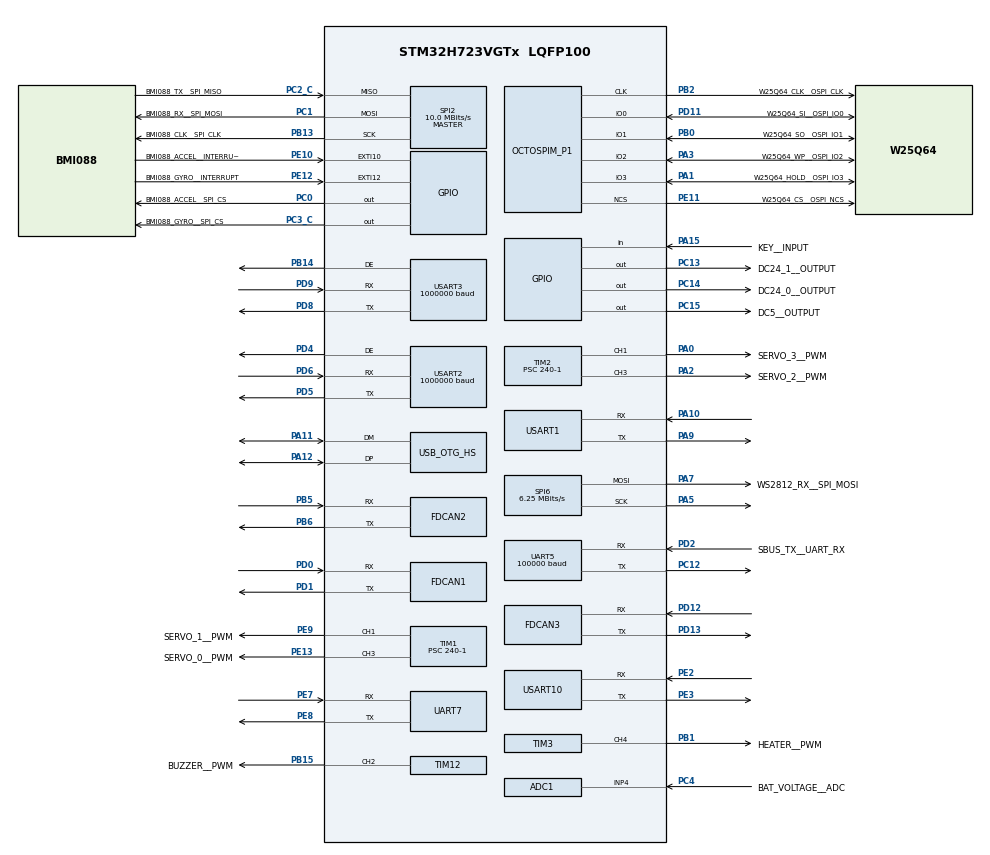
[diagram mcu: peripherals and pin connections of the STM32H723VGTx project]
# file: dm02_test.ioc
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ADC1.Channel-0\#ChannelRegularConversion=ADC_CHANNEL_4
ADC1.ClockPrescaler=ADC_CLOCK_ASYNC_DIV128
ADC1.ContinuousConvMode=ENABLE
ADC1.ConversionDataManagement=ADC_CONVERSIONDATA_DMA_CIRCULAR
ADC1.NbrOfConversion=1
ADC1.NbrOfConversionFlag=1
ADC1.OffsetNumber-0\#ChannelRegularConversion=ADC_OFFSET_NONE
ADC1.OffsetSignedSaturation-0\#ChannelRegularConversion=DISABLE
ADC1.Rank-0\#ChannelRegularConversion=1
ADC1.SamplingTime-0\#ChannelRegularConversion=ADC_SAMPLETIME_32CYCLES_5
ADC1.master=1
CORTEX_M7.BaseAddress_Spec=0x24000000
CORTEX_M7.CPU_DCache=Disabled
CORTEX_M7.CPU_ICache=Enabled
CORTEX_M7.DisableExec_Spec=MPU_INSTRUCTION_ACCESS_ENABLE
CORTEX_M7.IsBufferable_Spec=MPU_ACCESS_BUFFERABLE
CORTEX_M7.IsCacheable_Spec=MPU_ACCESS_CACHEABLE
CORTEX_M7.IsShareable_Spec=MPU_ACCESS_NOT_SHAREABLE
CORTEX_M7.MPU_Control=__NULL
CORTEX_M7.Size_Spec=MPU_REGION_SIZE_512KB
CORTEX_M7.SubRegionDisable_Spec=0x0
CORTEX_M7.TypeExtField_Spec=MPU_TEX_LEVEL1
CORTEX_M7.default_mode_Activation=1
Dma.ADC1.13.Direction=DMA_PERIPH_TO_MEMORY
Dma.ADC1.13.EventEnable=DISABLE
Dma.ADC1.13.FIFOMode=DMA_FIFOMODE_DISABLE
Dma.ADC1.13.Instance=DMA2_Stream5
Dma.ADC1.13.MemDataAlignment=DMA_MDATAALIGN_HALFWORD
Dma.ADC1.13.MemInc=DMA_MINC_ENABLE
Dma.ADC1.13.Mode=DMA_CIRCULAR
Dma.ADC1.13.PeriphDataAlignment=DMA_PDATAALIGN_HALFWORD
Dma.ADC1.13.PeriphInc=DMA_PINC_DISABLE
Dma.ADC1.13.Polarity=HAL_DMAMUX_REQ_GEN_RISING
Dma.ADC1.13.Priority=DMA_PRIORITY_LOW
Dma.ADC1.13.RequestNumber=1
Dma.ADC1.13.SignalID=NONE
Dma.ADC1.13.SyncEnable=DISABLE
Dma.ADC1.13.SyncPolarity=HAL_DMAMUX_SYNC_NO_EVENT
Dma.ADC1.13.SyncRequestNumber=1
Dma.ADC1.13.SyncSignalID=NONE
Dma.Request0=USART2_RX
Dma.Request1=USART2_TX
Dma.Request10=USART10_TX
Dma.Request11=SPI2_RX
Dma.Request12=SPI2_TX
Dma.Request13=ADC1
Dma.Request2=USART3_RX
Dma.Request3=USART3_TX
Dma.Request4=UART5_RX
Dma.Request5=USART1_RX
Dma.Request6=USART1_TX
Dma.Request7=UART7_RX
Dma.Request8=UART7_TX
Dma.Request9=USART10_RX
Dma.SPI2_RX.11.Direction=DMA_PERIPH_TO_MEMORY
Dma.SPI2_RX.11.EventEnable=DISABLE
Dma.SPI2_RX.11.FIFOMode=DMA_FIFOMODE_ENABLE
Dma.SPI2_RX.11.FIFOThreshold=DMA_FIFO_THRESHOLD_FULL
Dma.SPI2_RX.11.Instance=DMA2_Stream3
Dma.SPI2_RX.11.MemBurst=DMA_MBURST_SINGLE
Dma.SPI2_RX.11.MemDataAlignment=DMA_MDATAALIGN_BYTE
Dma.SPI2_RX.11.MemInc=DMA_MINC_ENABLE
Dma.SPI2_RX.11.Mode=DMA_NORMAL
Dma.SPI2_RX.11.PeriphBurst=DMA_PBURST_SINGLE
Dma.SPI2_RX.11.PeriphDataAlignment=DMA_PDATAALIGN_BYTE
Dma.SPI2_RX.11.PeriphInc=DMA_PINC_DISABLE
Dma.SPI2_RX.11.Polarity=HAL_DMAMUX_REQ_GEN_RISING
Dma.SPI2_RX.11.Priority=DMA_PRIORITY_LOW
Dma.SPI2_RX.11.RequestNumber=1
Dma.SPI2_RX.11.SignalID=NONE
Dma.SPI2_RX.11.SyncEnable=DISABLE
Dma.SPI2_RX.11.SyncPolarity=HAL_DMAMUX_SYNC_NO_EVENT
Dma.SPI2_RX.11.SyncRequestNumber=1
Dma.SPI2_RX.11.SyncSignalID=NONE
Dma.SPI2_TX.12.Direction=DMA_MEMORY_TO_PERIPH
Dma.SPI2_TX.12.EventEnable=DISABLE
Dma.SPI2_TX.12.FIFOMode=DMA_FIFOMODE_DISABLE
Dma.SPI2_TX.12.Instance=DMA2_Stream4
Dma.SPI2_TX.12.MemDataAlignment=DMA_MDATAALIGN_BYTE
Dma.SPI2_TX.12.MemInc=DMA_MINC_ENABLE
Dma.SPI2_TX.12.Mode=DMA_NORMAL
Dma.SPI2_TX.12.PeriphDataAlignment=DMA_PDATAALIGN_BYTE
Dma.SPI2_TX.12.PeriphInc=DMA_PINC_DISABLE
Dma.SPI2_TX.12.Polarity=HAL_DMAMUX_REQ_GEN_RISING
Dma.SPI2_TX.12.Priority=DMA_PRIORITY_LOW
Dma.SPI2_TX.12.RequestNumber=1
Dma.SPI2_TX.12.SignalID=NONE
Dma.SPI2_TX.12.SyncEnable=DISABLE
Dma.SPI2_TX.12.SyncPolarity=HAL_DMAMUX_SYNC_NO_EVENT
Dma.SPI2_TX.12.SyncRequestNumber=1
Dma.SPI2_TX.12.SyncSignalID=NONE
Dma.UART5_RX.4.Direction=DMA_PERIPH_TO_MEMORY
Dma.UART5_RX.4.EventEnable=DISABLE
Dma.UART5_RX.4.FIFOMode=DMA_FIFOMODE_ENABLE
Dma.UART5_RX.4.FIFOThreshold=DMA_FIFO_THRESHOLD_FULL
Dma.UART5_RX.4.Instance=DMA1_Stream4
Dma.UART5_RX.4.MemBurst=DMA_MBURST_SINGLE
Dma.UART5_RX.4.MemDataAlignment=DMA_MDATAALIGN_BYTE
Dma.UART5_RX.4.MemInc=DMA_MINC_ENABLE
Dma.UART5_RX.4.Mode=DMA_NORMAL
Dma.UART5_RX.4.PeriphBurst=DMA_PBURST_SINGLE
Dma.UART5_RX.4.PeriphDataAlignment=DMA_PDATAALIGN_BYTE
Dma.UART5_RX.4.PeriphInc=DMA_PINC_DISABLE
Dma.UART5_RX.4.Polarity=HAL_DMAMUX_REQ_GEN_RISING
Dma.UART5_RX.4.Priority=DMA_PRIORITY_LOW
Dma.UART5_RX.4.RequestNumber=1
Dma.UART5_RX.4.SignalID=NONE
Dma.UART5_RX.4.SyncEnable=DISABLE
Dma.UART5_RX.4.SyncPolarity=HAL_DMAMUX_SYNC_NO_EVENT
Dma.UART5_RX.4.SyncRequestNumber=1
Dma.UART5_RX.4.SyncSignalID=NONE
Dma.UART7_RX.7.Direction=DMA_PERIPH_TO_MEMORY
Dma.UART7_RX.7.EventEnable=DISABLE
Dma.UART7_RX.7.FIFOMode=DMA_FIFOMODE_ENABLE
Dma.UART7_RX.7.FIFOThreshold=DMA_FIFO_THRESHOLD_FULL
Dma.UART7_RX.7.Instance=DMA1_Stream7
Dma.UART7_RX.7.MemBurst=DMA_MBURST_SINGLE
Dma.UART7_RX.7.MemDataAlignment=DMA_MDATAALIGN_BYTE
Dma.UART7_RX.7.MemInc=DMA_MINC_ENABLE
Dma.UART7_RX.7.Mode=DMA_NORMAL
Dma.UART7_RX.7.PeriphBurst=DMA_PBURST_SINGLE
Dma.UART7_RX.7.PeriphDataAlignment=DMA_PDATAALIGN_BYTE
Dma.UART7_RX.7.PeriphInc=DMA_PINC_DISABLE
Dma.UART7_RX.7.Polarity=HAL_DMAMUX_REQ_GEN_RISING
Dma.UART7_RX.7.Priority=DMA_PRIORITY_LOW
Dma.UART7_RX.7.RequestNumber=1
Dma.UART7_RX.7.SignalID=NONE
Dma.UART7_RX.7.SyncEnable=DISABLE
Dma.UART7_RX.7.SyncPolarity=HAL_DMAMUX_SYNC_NO_EVENT
Dma.UART7_RX.7.SyncRequestNumber=1
Dma.UART7_RX.7.SyncSignalID=NONE
Dma.UART7_TX.8.Direction=DMA_MEMORY_TO_PERIPH
Dma.UART7_TX.8.EventEnable=DISABLE
Dma.UART7_TX.8.FIFOMode=DMA_FIFOMODE_ENABLE
Dma.UART7_TX.8.FIFOThreshold=DMA_FIFO_THRESHOLD_FULL
Dma.UART7_TX.8.Instance=DMA2_Stream0
Dma.UART7_TX.8.MemBurst=DMA_MBURST_SINGLE
Dma.UART7_TX.8.MemDataAlignment=DMA_MDATAALIGN_BYTE
Dma.UART7_TX.8.MemInc=DMA_MINC_ENABLE
Dma.UART7_TX.8.Mode=DMA_NORMAL
Dma.UART7_TX.8.PeriphBurst=DMA_PBURST_SINGLE
Dma.UART7_TX.8.PeriphDataAlignment=DMA_PDATAALIGN_BYTE
Dma.UART7_TX.8.PeriphInc=DMA_PINC_DISABLE
Dma.UART7_TX.8.Polarity=HAL_DMAMUX_REQ_GEN_RISING
Dma.UART7_TX.8.Priority=DMA_PRIORITY_LOW
Dma.UART7_TX.8.RequestNumber=1
Dma.UART7_TX.8.SignalID=NONE
Dma.UART7_TX.8.SyncEnable=DISABLE
Dma.UART7_TX.8.SyncPolarity=HAL_DMAMUX_SYNC_NO_EVENT
Dma.UART7_TX.8.SyncRequestNumber=1
Dma.UART7_TX.8.SyncSignalID=NONE
Dma.USART10_RX.9.Direction=DMA_PERIPH_TO_MEMORY
Dma.USART10_RX.9.EventEnable=DISABLE
Dma.USART10_RX.9.FIFOMode=DMA_FIFOMODE_DISABLE
Dma.USART10_RX.9.Instance=DMA2_Stream1
Dma.USART10_RX.9.MemDataAlignment=DMA_MDATAALIGN_BYTE
Dma.USART10_RX.9.MemInc=DMA_MINC_ENABLE
Dma.USART10_RX.9.Mode=DMA_NORMAL
Dma.USART10_RX.9.PeriphDataAlignment=DMA_PDATAALIGN_BYTE
Dma.USART10_RX.9.PeriphInc=DMA_PINC_DISABLE
Dma.USART10_RX.9.Polarity=HAL_DMAMUX_REQ_GEN_RISING
Dma.USART10_RX.9.Priority=DMA_PRIORITY_LOW
Dma.USART10_RX.9.RequestNumber=1
Dma.USART10_RX.9.SignalID=NONE
Dma.USART10_RX.9.SyncEnable=DISABLE
Dma.USART10_RX.9.SyncPolarity=HAL_DMAMUX_SYNC_NO_EVENT
Dma.USART10_RX.9.SyncRequestNumber=1
Dma.USART10_RX.9.SyncSignalID=NONE
Dma.USART10_TX.10.Direction=DMA_MEMORY_TO_PERIPH
Dma.USART10_TX.10.EventEnable=DISABLE
Dma.USART10_TX.10.FIFOMode=DMA_FIFOMODE_DISABLE
Dma.USART10_TX.10.Instance=DMA2_Stream2
Dma.USART10_TX.10.MemDataAlignment=DMA_MDATAALIGN_BYTE
Dma.USART10_TX.10.MemInc=DMA_MINC_ENABLE
Dma.USART10_TX.10.Mode=DMA_NORMAL
Dma.USART10_TX.10.PeriphDataAlignment=DMA_PDATAALIGN_BYTE
Dma.USART10_TX.10.PeriphInc=DMA_PINC_DISABLE
Dma.USART10_TX.10.Polarity=HAL_DMAMUX_REQ_GEN_RISING
Dma.USART10_TX.10.Priority=DMA_PRIORITY_LOW
Dma.USART10_TX.10.RequestNumber=1
Dma.USART10_TX.10.SignalID=NONE
Dma.USART10_TX.10.SyncEnable=DISABLE
Dma.USART10_TX.10.SyncPolarity=HAL_DMAMUX_SYNC_NO_EVENT
Dma.USART10_TX.10.SyncRequestNumber=1
Dma.USART10_TX.10.SyncSignalID=NONE
Dma.USART1_RX.5.Direction=DMA_PERIPH_TO_MEMORY
Dma.USART1_RX.5.EventEnable=DISABLE
Dma.USART1_RX.5.FIFOMode=DMA_FIFOMODE_ENABLE
Dma.USART1_RX.5.FIFOThreshold=DMA_FIFO_THRESHOLD_FULL
Dma.USART1_RX.5.Instance=DMA1_Stream5
Dma.USART1_RX.5.MemBurst=DMA_MBURST_SINGLE
Dma.USART1_RX.5.MemDataAlignment=DMA_MDATAALIGN_BYTE
Dma.USART1_RX.5.MemInc=DMA_MINC_ENABLE
Dma.USART1_RX.5.Mode=DMA_NORMAL
Dma.USART1_RX.5.PeriphBurst=DMA_PBURST_SINGLE
Dma.USART1_RX.5.PeriphDataAlignment=DMA_PDATAALIGN_BYTE
Dma.USART1_RX.5.PeriphInc=DMA_PINC_DISABLE
Dma.USART1_RX.5.Polarity=HAL_DMAMUX_REQ_GEN_RISING
Dma.USART1_RX.5.Priority=DMA_PRIORITY_LOW
Dma.USART1_RX.5.RequestNumber=1
Dma.USART1_RX.5.SignalID=NONE
Dma.USART1_RX.5.SyncEnable=DISABLE
Dma.USART1_RX.5.SyncPolarity=HAL_DMAMUX_SYNC_NO_EVENT
Dma.USART1_RX.5.SyncRequestNumber=1
Dma.USART1_RX.5.SyncSignalID=NONE
Dma.USART1_TX.6.Direction=DMA_MEMORY_TO_PERIPH
Dma.USART1_TX.6.EventEnable=DISABLE
Dma.USART1_TX.6.FIFOMode=DMA_FIFOMODE_ENABLE
Dma.USART1_TX.6.FIFOThreshold=DMA_FIFO_THRESHOLD_FULL
Dma.USART1_TX.6.Instance=DMA1_Stream6
Dma.USART1_TX.6.MemBurst=DMA_MBURST_SINGLE
Dma.USART1_TX.6.MemDataAlignment=DMA_MDATAALIGN_BYTE
Dma.USART1_TX.6.MemInc=DMA_MINC_ENABLE
Dma.USART1_TX.6.Mode=DMA_NORMAL
Dma.USART1_TX.6.PeriphBurst=DMA_PBURST_SINGLE
Dma.USART1_TX.6.PeriphDataAlignment=DMA_PDATAALIGN_BYTE
Dma.USART1_TX.6.PeriphInc=DMA_PINC_DISABLE
Dma.USART1_TX.6.Polarity=HAL_DMAMUX_REQ_GEN_RISING
Dma.USART1_TX.6.Priority=DMA_PRIORITY_LOW
Dma.USART1_TX.6.RequestNumber=1
Dma.USART1_TX.6.SignalID=NONE
Dma.USART1_TX.6.SyncEnable=DISABLE
Dma.USART1_TX.6.SyncPolarity=HAL_DMAMUX_SYNC_NO_EVENT
Dma.USART1_TX.6.SyncRequestNumber=1
Dma.USART1_TX.6.SyncSignalID=NONE
Dma.USART2_RX.0.Direction=DMA_PERIPH_TO_MEMORY
Dma.USART2_RX.0.EventEnable=DISABLE
Dma.USART2_RX.0.FIFOMode=DMA_FIFOMODE_ENABLE
Dma.USART2_RX.0.FIFOThreshold=DMA_FIFO_THRESHOLD_FULL
Dma.USART2_RX.0.Instance=DMA1_Stream1
Dma.USART2_RX.0.MemBurst=DMA_MBURST_SINGLE
Dma.USART2_RX.0.MemDataAlignment=DMA_MDATAALIGN_BYTE
Dma.USART2_RX.0.MemInc=DMA_MINC_ENABLE
Dma.USART2_RX.0.Mode=DMA_NORMAL
Dma.USART2_RX.0.PeriphBurst=DMA_PBURST_SINGLE
Dma.USART2_RX.0.PeriphDataAlignment=DMA_PDATAALIGN_BYTE
Dma.USART2_RX.0.PeriphInc=DMA_PINC_DISABLE
Dma.USART2_RX.0.Polarity=HAL_DMAMUX_REQ_GEN_RISING
Dma.USART2_RX.0.Priority=DMA_PRIORITY_LOW
Dma.USART2_RX.0.RequestNumber=1
Dma.USART2_RX.0.SignalID=NONE
Dma.USART2_RX.0.SyncEnable=DISABLE
Dma.USART2_RX.0.SyncPolarity=HAL_DMAMUX_SYNC_NO_EVENT
Dma.USART2_RX.0.SyncRequestNumber=1
Dma.USART2_RX.0.SyncSignalID=NONE
Dma.USART2_TX.1.Direction=DMA_MEMORY_TO_PERIPH
Dma.USART2_TX.1.EventEnable=DISABLE
Dma.USART2_TX.1.FIFOMode=DMA_FIFOMODE_ENABLE
Dma.USART2_TX.1.FIFOThreshold=DMA_FIFO_THRESHOLD_FULL
Dma.USART2_TX.1.Instance=DMA1_Stream0
Dma.USART2_TX.1.MemBurst=DMA_MBURST_SINGLE
Dma.USART2_TX.1.MemDataAlignment=DMA_MDATAALIGN_BYTE
Dma.USART2_TX.1.MemInc=DMA_MINC_ENABLE
Dma.USART2_TX.1.Mode=DMA_NORMAL
Dma.USART2_TX.1.PeriphBurst=DMA_PBURST_SINGLE
Dma.USART2_TX.1.PeriphDataAlignment=DMA_PDATAALIGN_BYTE
Dma.USART2_TX.1.PeriphInc=DMA_PINC_DISABLE
Dma.USART2_TX.1.Polarity=HAL_DMAMUX_REQ_GEN_RISING
Dma.USART2_TX.1.Priority=DMA_PRIORITY_LOW
Dma.USART2_TX.1.RequestNumber=1
Dma.USART2_TX.1.SignalID=NONE
Dma.USART2_TX.1.SyncEnable=DISABLE
Dma.USART2_TX.1.SyncPolarity=HAL_DMAMUX_SYNC_NO_EVENT
Dma.USART2_TX.1.SyncRequestNumber=1
Dma.USART2_TX.1.SyncSignalID=NONE
Dma.USART3_RX.2.Direction=DMA_PERIPH_TO_MEMORY
Dma.USART3_RX.2.EventEnable=DISABLE
Dma.USART3_RX.2.FIFOMode=DMA_FIFOMODE_ENABLE
Dma.USART3_RX.2.FIFOThreshold=DMA_FIFO_THRESHOLD_FULL
Dma.USART3_RX.2.Instance=DMA1_Stream2
Dma.USART3_RX.2.MemBurst=DMA_MBURST_SINGLE
Dma.USART3_RX.2.MemDataAlignment=DMA_MDATAALIGN_BYTE
Dma.USART3_RX.2.MemInc=DMA_MINC_ENABLE
Dma.USART3_RX.2.Mode=DMA_NORMAL
Dma.USART3_RX.2.PeriphBurst=DMA_PBURST_SINGLE
Dma.USART3_RX.2.PeriphDataAlignment=DMA_PDATAALIGN_BYTE
Dma.USART3_RX.2.PeriphInc=DMA_PINC_DISABLE
Dma.USART3_RX.2.Polarity=HAL_DMAMUX_REQ_GEN_RISING
Dma.USART3_RX.2.Priority=DMA_PRIORITY_LOW
Dma.USART3_RX.2.RequestNumber=1
Dma.USART3_RX.2.SignalID=NONE
Dma.USART3_RX.2.SyncEnable=DISABLE
Dma.USART3_RX.2.SyncPolarity=HAL_DMAMUX_SYNC_NO_EVENT
Dma.USART3_RX.2.SyncRequestNumber=1
Dma.USART3_RX.2.SyncSignalID=NONE
Dma.USART3_TX.3.Direction=DMA_MEMORY_TO_PERIPH
Dma.USART3_TX.3.EventEnable=DISABLE
Dma.USART3_TX.3.FIFOMode=DMA_FIFOMODE_ENABLE
Dma.USART3_TX.3.FIFOThreshold=DMA_FIFO_THRESHOLD_FULL
Dma.USART3_TX.3.Instance=DMA1_Stream3
Dma.USART3_TX.3.MemBurst=DMA_MBURST_SINGLE
Dma.USART3_TX.3.MemDataAlignment=DMA_MDATAALIGN_BYTE
Dma.USART3_TX.3.MemInc=DMA_MINC_ENABLE
Dma.USART3_TX.3.Mode=DMA_NORMAL
Dma.USART3_TX.3.PeriphBurst=DMA_PBURST_SINGLE
Dma.USART3_TX.3.PeriphDataAlignment=DMA_PDATAALIGN_BYTE
Dma.USART3_TX.3.PeriphInc=DMA_PINC_DISABLE
Dma.USART3_TX.3.Polarity=HAL_DMAMUX_REQ_GEN_RISING
Dma.USART3_TX.3.Priority=DMA_PRIORITY_LOW
Dma.USART3_TX.3.RequestNumber=1
Dma.USART3_TX.3.SignalID=NONE
Dma.USART3_TX.3.SyncEnable=DISABLE
Dma.USART3_TX.3.SyncPolarity=HAL_DMAMUX_SYNC_NO_EVENT
Dma.USART3_TX.3.SyncRequestNumber=1
Dma.USART3_TX.3.SyncSignalID=NONE
FDCAN1.AutoRetransmission=ENABLE
FDCAN1.CalculateBaudRateNominal=1000000
FDCAN1.CalculateTimeBitNominal=1000
FDCAN1.CalculateTimeQuantumNominal=25.0
FDCAN1.DataPrescaler=3
FDCAN1.DataSyncJumpWidth=10
FDCAN1.DataTimeSeg1=29
FDCAN1.DataTimeSeg2=10
FDCAN1.NominalPrescaler=3
FDCAN1.NominalSyncJumpWidth=10
FDCAN1.NominalTimeSeg1=29
FDCAN1.NominalTimeSeg2=10
FDCAN1.ProtocolException=DISABLE
FDCAN1.RxFifo0ElmtsNbr=16
FDCAN1.RxFifo1ElmtsNbr=0
FDCAN1.StdFiltersNbr=1
FDCAN1.TxFifoQueueElmtsNbr=8
FDCAN2.AutoRetransmission=ENABLE
FDCAN2.CalculateBaudRateNominal=1000000
FDCAN2.CalculateTimeBitNominal=1000
FDCAN2.CalculateTimeQuantumNominal=25.0
FDCAN2.DataPrescaler=3
FDCAN2.DataSyncJumpWidth=10
FDCAN2.DataTimeSeg1=29
FDCAN2.DataTimeSeg2=10
FDCAN2.MessageRAMOffset=853
FDCAN2.NominalPrescaler=3
FDCAN2.NominalSyncJumpWidth=10
FDCAN2.NominalTimeSeg1=29
FDCAN2.NominalTimeSeg2=10
FDCAN2.RxFifo0ElmtsNbr=16
FDCAN2.RxFifo1ElmtsNbr=0
FDCAN2.StdFiltersNbr=1
FDCAN2.TxFifoQueueElmtsNbr=8
FDCAN3.AutoRetransmission=ENABLE
FDCAN3.CalculateBaudRateNominal=1000000
FDCAN3.CalculateTimeBitNominal=1000
FDCAN3.CalculateTimeQuantumNominal=25.0
FDCAN3.DataPrescaler=3
FDCAN3.DataSyncJumpWidth=10
FDCAN3.DataTimeSeg1=29
FDCAN3.DataTimeSeg2=10
FDCAN3.MessageRAMOffset=1706
FDCAN3.NominalPrescaler=3
FDCAN3.NominalSyncJumpWidth=10
FDCAN3.NominalTimeSeg1=29
FDCAN3.NominalTimeSeg2=10
FDCAN3.RxFifo0ElmtsNbr=16
FDCAN3.RxFifo1ElmtsNbr=0
FDCAN3.StdFiltersNbr=1
FDCAN3.TxFifoQueueElmtsNbr=8
IWDG1.Prescaler=IWDG_PRESCALER_256
IWDG1.Reload=1023
IWDG1.Window=1023
Mcu.Family=STM32H7
Mcu.Name=STM32H723VGTx
Mcu.Package=LQFP100
Mdma.MDMA_Channel0.OCTOSPI2_FIFO_TH.0.BlockCount=0
Mdma.MDMA_Channel0.OCTOSPI2_FIFO_TH.0.BlockDataLength=0
Mdma.MDMA_Channel0.OCTOSPI2_FIFO_TH.0.BufferTransferLength=1
Mdma.MDMA_Channel0.OCTOSPI2_FIFO_TH.0.CircularMode=MDMA_LINEAR_LIST
Mdma.MDMA_Channel0.OCTOSPI2_FIFO_TH.0.DataAlignment=MDMA_DATAALIGN_PACKENABLE
Mdma.MDMA_Channel0.OCTOSPI2_FIFO_TH.0.DestBlockAddressOffset=0
Mdma.MDMA_Channel0.OCTOSPI2_FIFO_TH.0.DestBurst=MDMA_DEST_BURST_SINGLE
Mdma.MDMA_Channel0.OCTOSPI2_FIFO_TH.0.DestDataSize=MDMA_DEST_DATASIZE_BYTE
Mdma.MDMA_Channel0.OCTOSPI2_FIFO_TH.0.DestinationInc=MDMA_DEST_INC_BYTE
Mdma.MDMA_Channel0.OCTOSPI2_FIFO_TH.0.DstAddress=0
Mdma.MDMA_Channel0.OCTOSPI2_FIFO_TH.0.Endianness=MDMA_LITTLE_ENDIANNESS_PRESERVE
Mdma.MDMA_Channel0.OCTOSPI2_FIFO_TH.0.Instance=MDMA_Channel0
Mdma.MDMA_Channel0.OCTOSPI2_FIFO_TH.0.MaskAddress=0
Mdma.MDMA_Channel0.OCTOSPI2_FIFO_TH.0.MaskData=0
Mdma.MDMA_Channel0.OCTOSPI2_FIFO_TH.0.Priority=MDMA_PRIORITY_LOW
Mdma.MDMA_Channel0.OCTOSPI2_FIFO_TH.0.Rank=First
Mdma.MDMA_Channel0.OCTOSPI2_FIFO_TH.0.SourceBlockAddressOffset=0
Mdma.MDMA_Channel0.OCTOSPI2_FIFO_TH.0.SourceBurst=MDMA_SOURCE_BURST_SINGLE
Mdma.MDMA_Channel0.OCTOSPI2_FIFO_TH.0.SourceDataSize=MDMA_SRC_DATASIZE_BYTE
Mdma.MDMA_Channel0.OCTOSPI2_FIFO_TH.0.SourceInc=MDMA_SRC_INC_BYTE
Mdma.MDMA_Channel0.OCTOSPI2_FIFO_TH.0.SrcAddress=0
Mdma.MDMA_Channel0.OCTOSPI2_FIFO_TH.0.TransferTriggerMode=MDMA_BUFFER_TRANSFER
Mdma.MDMA_Channel0.Request0=OCTOSPI2_FIFO_TH
Mdma.MDMA_Channel0.RequestsNb=1
Mdma.RequestSet0=MDMA_Channel0
Mdma.RequestSetsNb=1
NVIC.DMA1_Stream0_IRQn=true\:0\:0\:false\:false\:true\:false\:true\:true
NVIC.DMA1_Stream1_IRQn=true\:0\:0\:false\:false\:true\:false\:true\:true
NVIC.DMA1_Stream2_IRQn=true\:0\:0\:false\:false\:true\:false\:true\:true
NVIC.DMA1_Stream3_IRQn=true\:0\:0\:false\:false\:true\:false\:true\:true
NVIC.DMA1_Stream4_IRQn=true\:0\:0\:false\:false\:true\:false\:true\:true
NVIC.DMA1_Stream5_IRQn=true\:0\:0\:false\:false\:true\:false\:true\:true
NVIC.DMA1_Stream6_IRQn=true\:0\:0\:false\:false\:true\:false\:true\:true
NVIC.DMA1_Stream7_IRQn=true\:0\:0\:false\:false\:true\:false\:true\:true
NVIC.DMA2_Stream0_IRQn=true\:0\:0\:false\:false\:true\:false\:true\:true
NVIC.DMA2_Stream1_IRQn=true\:0\:0\:false\:false\:true\:false\:true\:true
NVIC.DMA2_Stream2_IRQn=true\:0\:0\:false\:false\:true\:false\:true\:true
NVIC.DMA2_Stream3_IRQn=true\:0\:0\:false\:false\:true\:false\:true\:true
NVIC.DMA2_Stream4_IRQn=true\:0\:0\:false\:false\:true\:false\:true\:true
NVIC.DMA2_Stream5_IRQn=true\:0\:0\:false\:false\:true\:false\:true\:true
NVIC.EXTI15_10_IRQn=true\:0\:0\:true\:false\:true\:true\:true\:true
NVIC.FDCAN1_IT0_IRQn=true\:0\:0\:false\:false\:true\:true\:true\:true
NVIC.FDCAN1_IT1_IRQn=true\:0\:0\:false\:false\:true\:true\:true\:true
NVIC.FDCAN2_IT0_IRQn=true\:0\:0\:false\:false\:true\:true\:true\:true
NVIC.FDCAN2_IT1_IRQn=true\:0\:0\:false\:false\:true\:true\:true\:true
NVIC.FDCAN3_IT0_IRQn=true\:0\:0\:false\:false\:true\:true\:true\:true
NVIC.FDCAN3_IT1_IRQn=true\:0\:0\:false\:false\:true\:true\:true\:true
NVIC.MDMA_IRQn=true\:0\:0\:false\:false\:true\:false\:true\:true
NVIC.OCTOSPI2_IRQn=true\:0\:0\:false\:false\:true\:true\:true\:true
NVIC.OTG_HS_IRQn=true\:0\:0\:false\:false\:true\:false\:true\:true
NVIC.PriorityGroup=NVIC_PRIORITYGROUP_4
NVIC.SPI2_IRQn=true\:0\:0\:false\:false\:true\:false\:true\:true
NVIC.TIM4_IRQn=true\:5\:0\:true\:false\:true\:true\:true\:true
NVIC.TIM5_IRQn=true\:5\:0\:true\:false\:true\:true\:true\:true
NVIC.TIM6_DAC_IRQn=true\:5\:0\:true\:false\:true\:true\:true\:true
NVIC.TIM7_IRQn=true\:5\:0\:true\:false\:true\:true\:true\:true
NVIC.TIM8_UP_TIM13_IRQn=true\:5\:0\:true\:false\:true\:true\:true\:true
NVIC.UART5_IRQn=true\:0\:0\:true\:false\:true\:true\:true\:true
NVIC.UART7_IRQn=true\:0\:0\:true\:false\:true\:true\:true\:true
NVIC.USART10_IRQn=true\:0\:0\:true\:false\:true\:true\:true\:true
NVIC.USART1_IRQn=true\:0\:0\:true\:false\:true\:true\:true\:true
NVIC.USART2_IRQn=true\:0\:0\:true\:false\:true\:true\:true\:true
NVIC.USART3_IRQn=true\:0\:0\:true\:false\:true\:true\:true\:true
OCTOSPI2.ClockMode=HAL_OSPI_CLOCK_MODE_3
OCTOSPI2.ClockPrescaler=2
OCTOSPI2.DeviceSize=23
OCTOSPI2.FifoThreshold=1
OCTOSPI2.SampleShifting=HAL_OSPI_SAMPLE_SHIFTING_HALFCYCLE
PA0.GPIO_Label=SERVO_3__PWM
PA0.Signal=S_TIM2_CH1_ETR
PA1.GPIO_Label=W25Q64_HOLD__OSPI_IO3
PA1.Mode=OCTOSPI2_IOL_Port1L
PA1.Signal=OCTOSPIM_P1_IO3
PA10.Mode=Asynchronous
PA10.Signal=USART1_RX
PA11.Mode=Device_Only_FS
PA11.Signal=USB_OTG_HS_DM
PA12.Mode=Device_Only_FS
PA12.Signal=USB_OTG_HS_DP
PA13(JTMS/SWDIO).Mode=Serial_Wire
PA13(JTMS/SWDIO).Signal=DEBUG_JTMS-SWDIO
PA14(JTCK/SWCLK).Mode=Serial_Wire
PA14(JTCK/SWCLK).Signal=DEBUG_JTCK-SWCLK
PA15(JTDI).GPIO_Label=KEY__INPUT
PA15(JTDI).Signal=GPIO_Input
PA2.GPIO_Label=SERVO_2__PWM
PA2.Signal=S_TIM2_CH3
PA3.GPIO_Label=W25Q64_WP__OSPI_IO2
PA3.Mode=OCTOSPI2_IOL_Port1L
PA3.Signal=OCTOSPIM_P1_IO2
PA5.GPIO_Speed=GPIO_SPEED_FREQ_VERY_HIGH
PA5.Mode=TX_Only_Simplex_Unidirect_Master
PA5.Signal=SPI6_SCK
PA7.GPIO_Label=WS2812_RX__SPI_MOSI
PA7.GPIO_Speed=GPIO_SPEED_FREQ_VERY_HIGH
PA7.Mode=TX_Only_Simplex_Unidirect_Master
PA7.Signal=SPI6_MOSI
PA9.Mode=Asynchronous
PA9.Signal=USART1_TX
PB0.GPIO_Label=W25Q64_SO__OSPI_IO1
PB0.Mode=OCTOSPI2_IOL_Port1L
PB0.Signal=OCTOSPIM_P1_IO1
PB1.GPIO_Label=HEATER__PWM
PB1.Signal=S_TIM3_CH4
PB13.GPIO_Label=BMI088_CLK__SPI_CLK
PB13.GPIO_Speed=GPIO_SPEED_FREQ_VERY_HIGH
PB13.Mode=Full_Duplex_Master
PB13.Signal=SPI2_SCK
PB14.Mode=Hardware Flow Control (RS485)
PB14.Signal=USART3_DE
PB15.GPIO_Label=BUZZER__PWM
PB15.Signal=S_TIM12_CH2
PB2.GPIO_Label=W25Q64_CLK__OSPI_CLK
PB2.Mode=O2_P1_CLK
PB2.Signal=OCTOSPIM_P1_CLK
PB5.Mode=FDCAN_Activate
PB5.Signal=FDCAN2_RX
PB6.Mode=FDCAN_Activate
PB6.Signal=FDCAN2_TX
PC0.GPIO_Label=BMI088_ACCEL__SPI_CS
PC0.GPIO_Speed=GPIO_SPEED_FREQ_VERY_HIGH
PC0.PinState=GPIO_PIN_SET
PC0.Signal=GPIO_Output
PC1.GPIO_Label=BMI088_RX__SPI_MOSI
PC1.GPIO_Speed=GPIO_SPEED_FREQ_VERY_HIGH
PC1.Mode=Full_Duplex_Master
PC1.Signal=SPI2_MOSI
PC12.Mode=Asynchronous
PC12.Signal=UART5_TX
PC13.GPIO_Label=DC24_1__OUTPUT
PC13.PinState=GPIO_PIN_RESET
PC13.Signal=GPIO_Output
PC14-OSC32_IN.GPIO_Label=DC24_0__OUTPUT
PC14-OSC32_IN.Signal=GPIO_Output
PC15-OSC32_OUT.GPIO_Label=DC5__OUTPUT
PC15-OSC32_OUT.PinState=GPIO_PIN_RESET
PC15-OSC32_OUT.Signal=GPIO_Output
PC2_C.GPIO_Label=BMI088_TX__SPI_MISO
PC2_C.GPIO_Speed=GPIO_SPEED_FREQ_VERY_HIGH
PC2_C.Mode=Full_Duplex_Master
PC2_C.Signal=SPI2_MISO
PC3_C.GPIO_Label=BMI088_GYRO__SPI_CS
PC3_C.GPIO_Speed=GPIO_SPEED_FREQ_VERY_HIGH
PC3_C.PinState=GPIO_PIN_SET
PC3_C.Signal=GPIO_Output
PC4.GPIO_Label=BAT_VOLTAGE__ADC
PC4.Signal=ADCx_INP4
PD0.Mode=FDCAN_Activate
PD0.Signal=FDCAN1_RX
PD1.Mode=FDCAN_Activate
PD1.Signal=FDCAN1_TX
PD11.GPIO_Label=W25Q64_SI__OSPI_IO0
PD11.Mode=OCTOSPI2_IOL_Port1L
PD11.Signal=OCTOSPIM_P1_IO0
PD12.Mode=FDCAN_Activate
PD12.Signal=FDCAN3_RX
PD13.Mode=FDCAN_Activate
PD13.Signal=FDCAN3_TX
PD2.GPIO_Label=SBUS_TX__UART_RX
PD2.Mode=Asynchronous
PD2.Signal=UART5_RX
PD4.Mode=Hardware Flow Control (RS485)
PD4.Signal=USART2_DE
PD5.Mode=Asynchronous
PD5.Signal=USART2_TX
PD6.Mode=Asynchronous
PD6.Signal=USART2_RX
PD8.Mode=Asynchronous
PD8.Signal=USART3_TX
PD9.Mode=Asynchronous
PD9.Signal=USART3_RX
PE10.GPIO_Label=BMI088_ACCEL__INTERRUPT
PE10.Signal=GPXTI10
PE11.GPIO_Label=W25Q64_CS__OSPI_NCS
PE11.Mode=OCTOSPI2_Port1_NCS
PE11.Signal=OCTOSPIM_P1_NCS
PE12.GPIO_Label=BMI088_GYRO__INTERRUPT
PE12.Signal=GPXTI12
PE13.GPIO_Label=SERVO_0__PWM
PE13.Signal=S_TIM1_CH3
PE2.Mode=Asynchronous
PE2.Signal=USART10_RX
PE3.Mode=Asynchronous
PE3.Signal=USART10_TX
PE7.Mode=Asynchronous
PE7.Signal=UART7_RX
PE8.Mode=Asynchronous
PE8.Signal=UART7_TX
PE9.GPIO_Label=SERVO_1__PWM
PE9.Signal=S_TIM1_CH1
PH0-OSC_IN.Mode=HSE-External-Oscillator
PH0-OSC_IN.Signal=RCC_OSC_IN
PH1-OSC_OUT.Mode=HSE-External-Oscillator
PH1-OSC_OUT.Signal=RCC_OSC_OUT
ProjectManager.HeapSize=0x20000
ProjectManager.StackSize=0x10000
ProjectManager.TargetToolchain=STM32CubeIDE
RCC.ADCCLockSelection=RCC_ADCCLKSOURCE_CLKP
RCC.ADCFreq_Value=24000000
RCC.APB1Freq_Value=120000000
RCC.APB2Freq_Value=120000000
RCC.APB3Freq_Value=120000000
RCC.APB4Freq_Value=120000000
RCC.CKPERSourceSelection=RCC_CLKPSOURCE_HSE
RCC.CortexFreq_Value=480000000
RCC.D1PPRE=RCC_APB3_DIV2
RCC.D2PPRE1=RCC_APB1_DIV2
RCC.D2PPRE2=RCC_APB2_DIV2
RCC.D3PPRE=RCC_APB4_DIV2
RCC.DIVM1=2
RCC.DIVM2=12
RCC.DIVM3=24
RCC.DIVN1=40
RCC.DIVN2=100
RCC.DIVN3=160
RCC.DIVP1=1
RCC.DIVQ1=4
RCC.DIVQ2=4
RCC.HCLKFreq_Value=240000000
RCC.HPRE=RCC_HCLK_DIV2
RCC.HSE_VALUE=24000000
RCC.PLL2FRACN=0
RCC.PLLFRACN=0
RCC.PLLSourceVirtual=RCC_PLLSOURCE_HSE
RCC.SPI123CLockSelection=RCC_SPI123CLKSOURCE_PLL3
RCC.SPI6CLockSelection=RCC_SPI6CLKSOURCE_PLL2
RCC.SYSCLKFreq_VALUE=480000000
RCC.SYSCLKSource=RCC_SYSCLKSOURCE_PLLCLK
RCC.USBCLockSelection=RCC_USBCLKSOURCE_HSI48
RCC.USBFreq_Value=48000000
SH.ADCx_INP4.0=ADC1_INP4,IN4-Single-Ended
SH.S_TIM12_CH2.0=TIM12_CH2,PWM Generation2 CH2
SH.S_TIM1_CH1.0=TIM1_CH1,PWM Generation1 CH1
SH.S_TIM1_CH3.0=TIM1_CH3,PWM Generation3 CH3
SH.S_TIM2_CH1_ETR.0=TIM2_CH1,PWM Generation1 CH1
SH.S_TIM2_CH3.0=TIM2_CH3,PWM Generation3 CH3
SH.S_TIM3_CH4.0=TIM3_CH4,PWM Generation4 CH4
SPI2.BaudRatePrescaler=SPI_BAUDRATEPRESCALER_8
SPI2.CLKPhase=SPI_PHASE_2EDGE
SPI2.CLKPolarity=SPI_POLARITY_HIGH
SPI2.CalculateBaudRate=10.0 MBits/s
SPI2.DataSize=SPI_DATASIZE_8BIT
SPI2.Direction=SPI_DIRECTION_2LINES
SPI2.Mode=SPI_MODE_MASTER
SPI2.VirtualType=VM_MASTER
SPI6.BaudRatePrescaler=SPI_BAUDRATEPRESCALER_8
SPI6.CLKPolarity=SPI_POLARITY_LOW
SPI6.CalculateBaudRate=6.25 MBits/s
SPI6.DataSize=SPI_DATASIZE_8BIT
SPI6.Direction=SPI_DIRECTION_2LINES_TXONLY
SPI6.FirstBit=SPI_FIRSTBIT_MSB
SPI6.Mode=SPI_MODE_MASTER
SPI6.VirtualType=VM_MASTER
STMicroelectronics.X-CUBE-ALGOBUILD.1.4.0.LibraryCcDSPOoLibraryJjDSPOoLibrary=true
TIM1.AutoReloadPreload=TIM_AUTORELOAD_PRELOAD_ENABLE
TIM1.Channel-PWM\ Generation1\ CH1=TIM_CHANNEL_1
TIM1.Channel-PWM\ Generation3\ CH3=TIM_CHANNEL_3
TIM1.OC1Preload_PWM=DISABLE
TIM1.OC3Preload_PWM=DISABLE
TIM1.Period=10000-1
TIM1.Prescaler=240-1
TIM12.Channel-PWM\ Generation2\ CH2=TIM_CHANNEL_2
TIM12.OC2Preload_PWM=DISABLE
TIM12.Period=250-1
TIM12.Prescaler=240-1
TIM2.AutoReloadPreload=TIM_AUTORELOAD_PRELOAD_ENABLE
TIM2.Channel-PWM\ Generation1\ CH1=TIM_CHANNEL_1
TIM2.Channel-PWM\ Generation3\ CH3=TIM_CHANNEL_3
TIM2.OC1Preload_PWM=DISABLE
TIM2.OC3Preload_PWM=DISABLE
TIM2.Period=10000-1
TIM2.Prescaler=240-1
TIM3.Channel-PWM\ Generation4\ CH4=TIM_CHANNEL_4
TIM3.Period=10000-1
TIM3.Prescaler=240-1
TIM4.Period=10-1
TIM4.Prescaler=240-1
TIM5.Period=3600000000-1
TIM5.Prescaler=240-1
TIM6.Period=10000-1
TIM6.Prescaler=24000-1
TIM7.Period=1000-1
TIM7.Prescaler=240-1
TIM8.Period=125-1
TIM8.Prescaler=240-1
UART5.BaudRate=100000
UART5.Mode=MODE_RX
UART5.Parity=PARITY_EVEN
UART5.StopBits=UART_STOPBITS_2
UART5.WordLength=WORDLENGTH_9B
USART1.VirtualMode-Asynchronous=VM_ASYNC
USART10.VirtualMode=VM_ASYNC
USART2.BaudRate=1000000
USART2.VirtualMode-Asynchronous=VM_ASYNC
USART2.VirtualMode-Hardware\ Flow\ Control\ (RS485)=VM_ASYNC
USART3.BaudRate=1000000
USART3.VirtualMode-Asynchronous=VM_ASYNC
USART3.VirtualMode-Hardware\ Flow\ Control\ (RS485)=VM_ASYNC
USB_DEVICE.CLASS_NAME_HS=CDC
USB_DEVICE.MANUFACTURER_STRING=DM_MC02_test_FS
USB_DEVICE.PRODUCT_STRING_CDC_HS=DM_MC02_test_HS
USB_DEVICE.USBD_LPM_ENABLED=1
USB_DEVICE.USBD_MAX_NUM_INTERFACES=1
USB_DEVICE.USBD_SELF_POWERED=1
USB_DEVICE.VirtualMode=Cdc
USB_DEVICE.VirtualModeHS=Cdc_HS
USB_OTG_HS.VirtualMode-Device_Only_FS=Device_Only_FS
USB_OTG_HS.dma_enable-Device_Only_FS=DISABLE
VP_CORDIC_VS_CORDIC.Mode=CORDIC_Activate
VP_IWDG1_VS_IWDG.Mode=IWDG_Activate
VP_MEMORYMAP_VS_MEMORYMAP.Mode=CurAppReg
VP_OCTOSPI2_VS_octo.Mode=octo_mode
VP_STMicroelectronics.X-CUBE-ALGOBUILD_VS_DSPOoLibraryJjLibrary_1.4.0_1.4.0.Mode=DSPOoLibraryJjLibrary
VP_TIM4_VS_ClockSourceINT.Mode=Internal
VP_TIM5_VS_ClockSourceINT.Mode=Internal
VP_TIM6_VS_ClockSourceINT.Mode=Enable_Timer
VP_TIM7_VS_ClockSourceINT.Mode=Enable_Timer
VP_TIM8_VS_ClockSourceINT.Mode=Internal
VP_USB_DEVICE_VS_USB_DEVICE_CDC_HS.Mode=CDC_HS
board=custom

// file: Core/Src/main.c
/* USER CODE BEGIN Header */
/**
  ******************************************************************************
  * @file           : main.c
  * @brief          : Main program body
  ******************************************************************************
  * @attention
  *
  * Copyright (c) 2025 STMicroelectronics.
  * All rights reserved.
  *
  * This software is licensed under terms that can be found in the LICENSE file
  * in the root directory of this software component.
  * If no LICENSE file comes with this software, it is provided AS-IS.
  *
  ******************************************************************************
  */
/* USER CODE END Header */
#include "main.h"
#include "adc.h"
#include "cordic.h"
#include "dma.h"
#include "fdcan.h"
#include "iwdg.h"
#include "mdma.h"
#include "octospi.h"
#include "spi.h"
#include "tim.h"
#include "usart.h"
#include "usb_device.h"
#include "gpio.h"

void SystemClock_Config(void);
void PeriphCommonClock_Config(void);

int main(void)
{

  /* Enable the CPU Cache */

  /* Enable I-Cache---------------------------------------------------------*/
  SCB_EnableICache();

  /* MCU Configuration--------------------------------------------------------*/

  /* Reset of all peripherals, Initializes the Flash interface and the Systick. */
  HAL_Init();

  /* Configure the system clock */
  SystemClock_Config();

  /* Configure the peripherals common clocks */
  PeriphCommonClock_Config();

  /* Initialize all configured peripherals */
  MX_GPIO_Init();
  MX_DMA_Init();
  MX_MDMA_Init();
  MX_USB_DEVICE_Init();
  MX_ADC1_Init();
  MX_FDCAN1_Init();
  MX_FDCAN2_Init();
  MX_FDCAN3_Init();
  MX_USART1_UART_Init();
  MX_USART2_UART_Init();
  MX_USART3_UART_Init();
  MX_UART5_Init();
  MX_UART7_Init();
  MX_USART10_UART_Init();
  MX_SPI2_Init();
  MX_SPI6_Init();
  MX_IWDG1_Init();
  MX_TIM1_Init();
  MX_TIM2_Init();
  MX_TIM3_Init();
  MX_TIM5_Init();
  MX_TIM6_Init();
  MX_TIM12_Init();
  MX_TIM7_Init();
  MX_TIM8_Init();
  MX_CORDIC_Init();
  MX_OCTOSPI2_Init();
  MX_TIM4_Init();
  /* USER CODE BEGIN 2 */

    Task_Init();

  /* USER CODE END 2 */

  /* Infinite loop */
  /* USER CODE BEGIN WHILE */
    while (1)
    {
        Task_Loop();
    /* USER CODE END WHILE */

    }
}

void SystemClock_Config(void)
{
  RCC_OscInitTypeDef RCC_OscInitStruct = {0};
  RCC_ClkInitTypeDef RCC_ClkInitStruct = {0};

  /** Supply configuration update enable
  */
  HAL_PWREx_ConfigSupply(PWR_LDO_SUPPLY);

  /** Configure the main internal regulator output voltage
  */
  __HAL_PWR_VOLTAGESCALING_CONFIG(PWR_REGULATOR_VOLTAGE_SCALE0);

  while(!__HAL_PWR_GET_FLAG(PWR_FLAG_VOSRDY)) {}

  /** Initializes the RCC Oscillators according to the specified parameters
  * in the RCC_OscInitTypeDef structure.
  */
  RCC_OscInitStruct.OscillatorType = RCC_OSCILLATORTYPE_HSI48|RCC_OSCILLATORTYPE_LSI
                              |RCC_OSCILLATORTYPE_HSE;
  RCC_OscInitStruct.HSEState = RCC_HSE_ON;
  RCC_OscInitStruct.LSIState = RCC_LSI_ON;
  RCC_OscInitStruct.HSI48State = RCC_HSI48_ON;
  RCC_OscInitStruct.PLL.PLLState = RCC_PLL_ON;
  RCC_OscInitStruct.PLL.PLLSource = RCC_PLLSOURCE_HSE;
  RCC_OscInitStruct.PLL.PLLM = 2;
  RCC_OscInitStruct.PLL.PLLN = 40;
  RCC_OscInitStruct.PLL.PLLP = 1;
  RCC_OscInitStruct.PLL.PLLQ = 4;
  RCC_OscInitStruct.PLL.PLLR = 2;
  RCC_OscInitStruct.PLL.PLLRGE = RCC_PLL1VCIRANGE_3;
  RCC_OscInitStruct.PLL.PLLVCOSEL = RCC_PLL1VCOWIDE;
  RCC_OscInitStruct.PLL.PLLFRACN = 0;
  if (HAL_RCC_OscConfig(&RCC_OscInitStruct) != HAL_OK)
  {
    Error_Handler();
  }

  /** Initializes the CPU, AHB and APB buses clocks
  */
  RCC_ClkInitStruct.ClockType = RCC_CLOCKTYPE_HCLK|RCC_CLOCKTYPE_SYSCLK
                              |RCC_CLOCKTYPE_PCLK1|RCC_CLOCKTYPE_PCLK2
                              |RCC_CLOCKTYPE_D3PCLK1|RCC_CLOCKTYPE_D1PCLK1;
  RCC_ClkInitStruct.SYSCLKSource = RCC_SYSCLKSOURCE_PLLCLK;
  RCC_ClkInitStruct.SYSCLKDivider = RCC_SYSCLK_DIV1;
  RCC_ClkInitStruct.AHBCLKDivider = RCC_HCLK_DIV2;
  RCC_ClkInitStruct.APB3CLKDivider = RCC_APB3_DIV2;
  RCC_ClkInitStruct.APB1CLKDivider = RCC_APB1_DIV2;
  RCC_ClkInitStruct.APB2CLKDivider = RCC_APB2_DIV2;
  RCC_ClkInitStruct.APB4CLKDivider = RCC_APB4_DIV2;

  if (HAL_RCC_ClockConfig(&RCC_ClkInitStruct, FLASH_LATENCY_3) != HAL_OK)
  {
    Error_Handler();
  }
}

void PeriphCommonClock_Config(void)
{
  RCC_PeriphCLKInitTypeDef PeriphClkInitStruct = {0};

  /** Initializes the peripherals clock
  */
  PeriphClkInitStruct.PeriphClockSelection = RCC_PERIPHCLK_CKPER;
  PeriphClkInitStruct.CkperClockSelection = RCC_CLKPSOURCE_HSE;
  if (HAL_RCCEx_PeriphCLKConfig(&PeriphClkInitStruct) != HAL_OK)
  {
    Error_Handler();
  }
}

void Error_Handler(void)
{
    __disable_irq();
    while (1)
    {
    }
}
